# sifive_hifive_unmatched_a00 register map
Vendor: sifive; File version: 0.1
From sifive,hifive-unmatched-a00,model device generator
Registers are 32-bit, read-write, no defined reset value unless marked. A register's access mark holds for its fields unless they carry their own. Offsets are from the block's base; lines under a group give offsets from that group; [hi:lo] are bit positions; {n}, {i} and the like mark numbered series; 'fields as' and 'values as' point back to an identical list; <NAME> marks a mode.

## Memory map
0x00004000 sifive_test0_0 size 0x1000 — From sifive,test0,control peripheral generator
0x02000000 riscv_clint0_0 size 0x10000 — From riscv,clint0,control peripheral generator
0x02010000 sifive_ccache0_0 size 0x4000 — From sifive,ccache0,control peripheral generator
0x0C000000 riscv_plic0_0 size 0x4000000 — From riscv,plic0,control peripheral generator
0x10010000 sifive_uart0_0 size 0x1000 — From sifive,uart0,control peripheral generator
0x10011000 sifive_uart0_1 size 0x1000 — From sifive,uart0,control peripheral generator
0x10020000 sifive_pwm0_0 size 0x1000 — From sifive,pwm0,control peripheral generator
0x10021000 sifive_pwm0_1 size 0x1000 — From sifive,pwm0,control peripheral generator
0x10030000 sifive_i2c0_0 size 0x1000 — From sifive,i2c0,control peripheral generator
0x10031000 sifive_i2c0_1 size 0x1000 — From sifive,i2c0,control peripheral generator
0x10040000 sifive_spi0_0 size 0x1000 — From sifive,spi0,control peripheral generator
0x10041000 sifive_spi0_1 size 0x1000 — From sifive,spi0,control peripheral generator
0x10050000 sifive_spi0_2 size 0x1000 — From sifive,spi0,control peripheral generator
0x10060000 sifive_gpio0_0 size 0x1000 — From sifive,gpio0,control peripheral generator

## sifive_ccache0_0 — From sifive,ccache0,control peripheral generator
Base 0x02010000
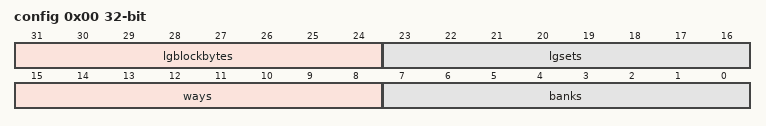
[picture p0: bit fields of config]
0x00 config — Information about the Cache Configuration
  [31:24] lgblockbytes ro — Base-2 logarithm of the bytes per cache block
  [23:16] lgsets ro — Base-2 logarithm of the sets per bank
  [15:8] ways ro — Number of ways per bank
  [7:0] banks ro — Number of banks in the cache
0x08 wayenable — The index of the largest way which has been enabled. May only be increased.
0x2000 l2perfevent0 — The L2 performance event0 control register.
0x2008 l2perfevent1 — The L2 performance event1 control register.
0x2800 l2clientfilter — The L2 Client Filterregister.
0x3000 l2pmcounter0 — The L2 performance monitor counter0 register.
0x3008 l2pmcounter1 — The L2 performance monitor counter1 register.
0x31F8 l2pmcounter63 — The L2 performance monitor counter63 register.

## riscv_clint0_0 — From riscv,clint0,control peripheral generator
Base 0x02000000
{0x0+4i} msip_{i} (i=0..4) — MSIP Register for hart {i}
{0x4000+8i} mtimecmp_{i} 64-bit (i=0..4) — MTIMECMP Register for hart {i}
0xBFF8 mtime 64-bit

## sifive_gpio0_0 — From sifive,gpio0,control peripheral generator
Base 0x10060000
0x00 input_val — Pin value
0x04 input_en — Pin input enable
0x08 output_en — Pin output enable
0x0C output_val — Output value
0x10 pue — Internal pull-up enable
0x14 ds — Pin drive strength
0x18 rise_ie — Rise interrupt enable
0x1C rise_ip — Rise interrupt pending
0x20 fall_ie — Fall interrupt enable
0x24 fall_ip — Fall interrupt pending
0x28 high_ie — High interrupt enable
0x2C high_ip — High interrupt pending
0x30 low_ie — Low interrupt enable
0x34 low_ip — Low interrupt pending
0x38 iof_en — I/O function enable
0x3C iof_sel — I/O function select
0x40 out_xor — Output XOR (invert)

## sifive_i2c0_0 — From sifive,i2c0,control peripheral generator
Base 0x10030000
Same registers: sifive_i2c0_1 0x10031000
0x00 prescale_low — Clock Prescale register lo-byte
0x04 prescale_high — Clock Prescale register hi-byte
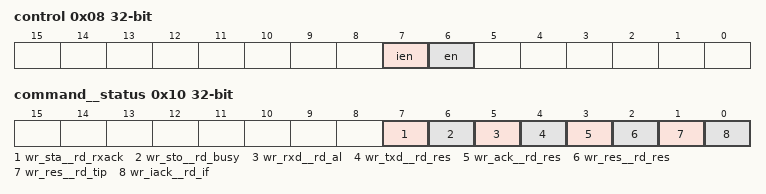
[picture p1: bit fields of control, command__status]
0x08 control
  [7] ien — I2C core interrupt enable bit
  [6] en — I2C core enable bit
0x0C transmit__receive — Transmit and receive data byte register
0x10 command__status — Command write and status read register
  [7] wr_sta__rd_rxack — Generate start and Got ACK/NACK
  [6] wr_sto__rd_busy — Generate stop and I2C bus busy
  [5] wr_rxd__rd_al — Receive data and Arbitration lost
  [4] wr_txd__rd_res — Transmit data and Reserved
  [3] wr_ack__rd_res — Send ACK/NACK and Reserved
  [2] wr_res__rd_res — Reserved and Reserved
  [1] wr_res__rd_tip — Reserved and Transfer in progress
  [0] wr_iack__rd_if — Clear interrupt and Interrupt pending
